# ATmega128A register map
Vendor: Atmel; File version: 1.0
CPU: other r0p0, little endian, no MPU, no FPU, 4 interrupt priority bits
Registers are 8-bit, read-write, reset 0x0 unless marked. A register's access mark holds for its fields unless they carry their own. Offsets are from the block's base; [hi:lo] are bit positions; {n}, {i} and the like mark numbered series.

## MISC — Other Registers
Base 0x00000040
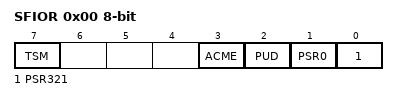
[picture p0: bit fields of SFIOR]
0x00 SFIOR — Special Function IO Register
  [7] TSM — Timer/Counter Synchronization Mode
  [3] ACME — Analog Comparator Multiplexer Enable
  [2] PUD — Pull Up Disable
  [1] PSR0 — Prescaler Reset Timer/Counter0
  [0] PSR321 — Prescaler Reset Timer/Counter3, Timer/Counter2, and Timer/Counter1

## PORTA — I/O Port
Base 0x00000039
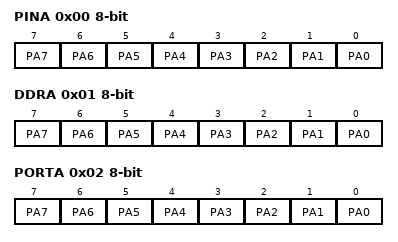
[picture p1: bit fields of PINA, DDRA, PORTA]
0x00 PINA — Port A Input Pins
  [n] PA{n} (n=0..7) — Pin A{n}
0x01 DDRA — Port A Data Direction Register
  [n] PA{n} (n=0..7) — Pin A{n}
0x02 PORTA — Port A Data Register
  [n] PA{n} (n=0..7) — Pin A{n}

## PORTB — I/O Port
Base 0x00000036
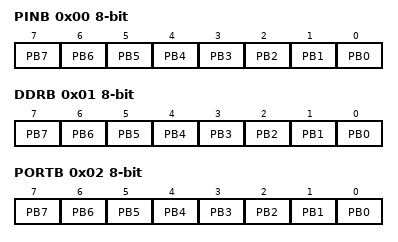
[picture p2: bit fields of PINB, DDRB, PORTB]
0x00 PINB — Port B Input Pins
  [n] PB{n} (n=0..7) — Pin B{n}
0x01 DDRB — Port B Data Direction Register
  [n] PB{n} (n=0..7) — Pin B{n}
0x02 PORTB — Port B Data Register
  [n] PB{n} (n=0..7) — Pin B{n}

## PORTC — I/O Port
Base 0x00000033
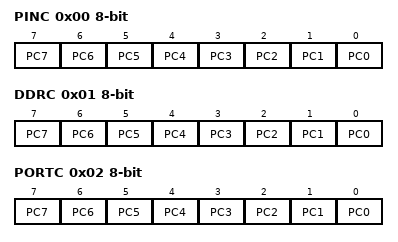
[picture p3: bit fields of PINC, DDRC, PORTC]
0x00 PINC — Port C Input Pins
  [n] PC{n} (n=0..7) — Pin C{n}
0x01 DDRC — Port C Data Direction Register
  [n] PC{n} (n=0..7) — Pin C{n}
0x02 PORTC — Port C Data Register
  [n] PC{n} (n=0..7) — Pin C{n}

## PORTD — I/O Port
Base 0x00000030
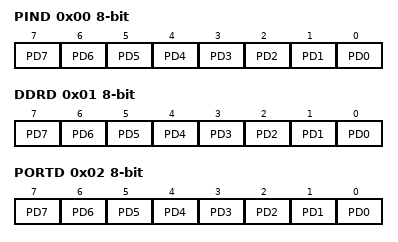
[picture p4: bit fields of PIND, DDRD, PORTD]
0x00 PIND — Port D Input Pins
  [n] PD{n} (n=0..7) — Pin D{n}
0x01 DDRD — Port D Data Direction Register
  [n] PD{n} (n=0..7) — Pin D{n}
0x02 PORTD — Port D Data Register
  [n] PD{n} (n=0..7) — Pin D{n}

## PORTE — I/O Port
Base 0x00000021
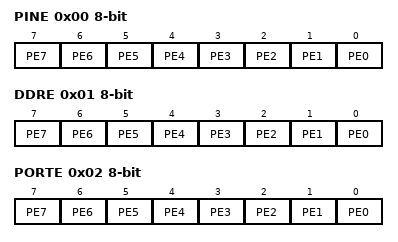
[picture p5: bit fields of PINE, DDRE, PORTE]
0x00 PINE — Input Pins, Port E
  [n] PE{n} (n=0..7) — Pin E{n}
0x01 DDRE — Data Direction Register, Port E
  [n] PE{n} (n=0..7) — Pin E{n}
0x02 PORTE — Data Register, Port E
  [n] PE{n} (n=0..7) — Pin E{n}

## PORTF — I/O Port
Base 0x00000020
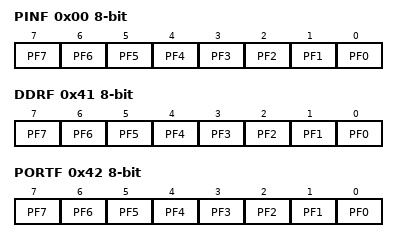
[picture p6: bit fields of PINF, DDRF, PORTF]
0x00 PINF — Input Pins, Port F
  [n] PF{n} (n=0..7) — Pin F{n}
0x41 DDRF — Data Direction Register, Port F
  [n] PF{n} (n=0..7) — Pin F{n}
0x42 PORTF — Data Register, Port F
  [n] PF{n} (n=0..7) — Pin F{n}

## PORTG — I/O Port
Base 0x00000063
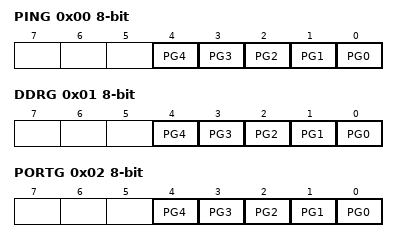
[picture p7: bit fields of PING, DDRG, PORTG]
0x00 PING — Input Pins, Port G
  [n] PG{n} (n=0..4) — Pin G{n}
0x01 DDRG — Data Direction Register, Port G
  [n] PG{n} (n=0..4) — Pin G{n}
0x02 PORTG — Data Register, Port G
  [n] PG{n} (n=0..4) — Pin G{n}

## SPI — Serial Peripheral Interface
Base 0x0000002D
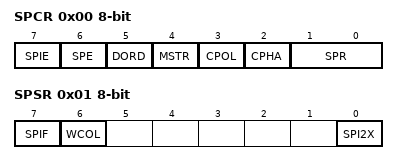
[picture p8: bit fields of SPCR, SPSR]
0x00 SPCR — SPI Control Register
  [7] SPIE — SPI Interrupt Enable
  [6] SPE — SPI Enable
  [5] DORD — Data Order
  [4] MSTR — Master/Slave Select
  [3] CPOL — Clock polarity
  [2] CPHA — Clock Phase
  [1:0] SPR — SPI Clock Rate Selects
    0=fosc/4; 1=fosc/16; 2=fosc/64; 3=fosc/128
0x01 SPSR — SPI Status Register
  [7] SPIF — SPI Interrupt Flag
  [6] WCOL — Write Collision Flag
  [0] SPI2X — Double SPI Speed Bit
0x02 SPDR — SPI Data Register

## TC0 — Timer/Counter, 8-bit Async
Base 0x00000040
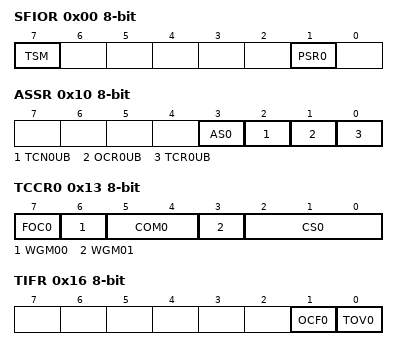
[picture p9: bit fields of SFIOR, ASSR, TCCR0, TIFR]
0x00 SFIOR — Special Function IO Register
  [7] TSM — Timer/Counter Synchronization Mode
  [1] PSR0 — Prescaler Reset Timer/Counter0
0x10 ASSR — Asynchronus Status Register
  [3] AS0 — Asynchronus Timer/Counter 0
  [2] TCN0UB — Timer/Counter0 Update Busy
  [1] OCR0UB — Output Compare register 0 Busy
  [0] TCR0UB — Timer/Counter Control Register 0 Update Busy
0x11 OCR0 — Output Compare Register
0x12 TCNT0 — Timer/Counter Register
0x13 TCCR0 — Timer/Counter Control Register
  [7] FOC0 — Force Output Compare
  [6] WGM00 — Waveform Generation Mode 0
    0=Normal; 1=CTC
  [5:4] COM0 — Compare Match Output Modes
  [3] WGM01 — Waveform Generation Mode 1
  [2:0] CS0 — Clock Selects
    0=No Clock Source (Stopped); 1=Running, No Prescaling; 2=Running, CLK/8; 3=Running, CLK/32; 4=Running, CLK/64; 5=Running, CLK/128; 6=Running, CLK/256; 7=Running, CLK/1024
0x16 TIFR — Timer/Counter Interrupt Flag register
  [1] OCF0 — Output Compare Flag 0
  [0] TOV0 — Timer/Counter0 Overflow Flag
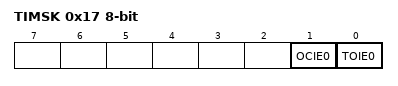
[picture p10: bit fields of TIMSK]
0x17 TIMSK — Timer/Counter Interrupt Mask Register
  [1] OCIE0 — Timer/Counter0 Output Compare Match Interrupt register
  [0] TOIE0 — Timer/Counter0 Overflow Interrupt Enable
